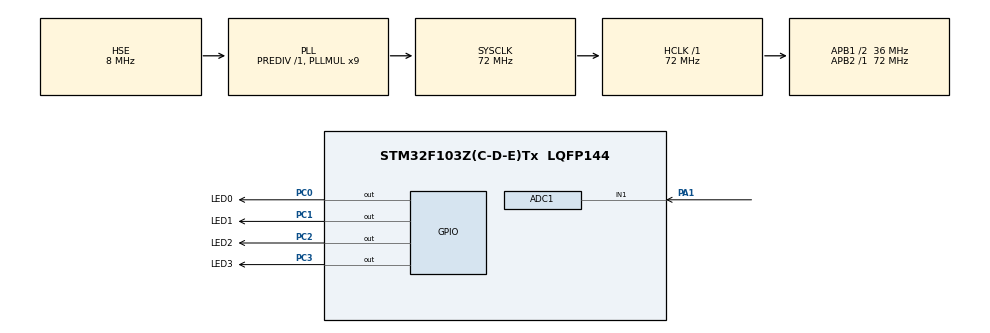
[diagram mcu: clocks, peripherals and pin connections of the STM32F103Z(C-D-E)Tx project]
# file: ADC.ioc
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ADC1.Channel-4\#ChannelRegularConversion=ADC_CHANNEL_1
ADC1.NbrOfConversionFlag=1
ADC1.Rank-4\#ChannelRegularConversion=1
ADC1.SamplingTime-4\#ChannelRegularConversion=ADC_SAMPLETIME_1CYCLE_5
ADC1.master=1
Mcu.Family=STM32F1
Mcu.Name=STM32F103Z(C-D-E)Tx
Mcu.Package=LQFP144
NVIC.ADC1_2_IRQn=true\:0\:0\:false\:false\:true\:true\:true
NVIC.PriorityGroup=NVIC_PRIORITYGROUP_4
OSC_IN.Mode=HSE-External-Oscillator
OSC_IN.Signal=RCC_OSC_IN
OSC_OUT.Mode=HSE-External-Oscillator
OSC_OUT.Signal=RCC_OSC_OUT
PA1.Signal=ADCx_IN1
PA13.Mode=Serial_Wire
PA13.Signal=SYS_JTMS-SWDIO
PA14.Mode=Serial_Wire
PA14.Signal=SYS_JTCK-SWCLK
PC0.GPIO_Label=LED0
PC0.GPIO_ModeDefaultOutputPP=GPIO_MODE_OUTPUT_PP
PC0.GPIO_PuPd=GPIO_NOPULL
PC0.GPIO_Speed=GPIO_SPEED_FREQ_LOW
PC0.PinState=GPIO_PIN_SET
PC0.Signal=GPIO_Output
PC1.GPIO_Label=LED1
PC1.GPIO_ModeDefaultOutputPP=GPIO_MODE_OUTPUT_PP
PC1.GPIO_PuPd=GPIO_NOPULL
PC1.GPIO_Speed=GPIO_SPEED_FREQ_LOW
PC1.PinState=GPIO_PIN_SET
PC1.Signal=GPIO_Output
PC2.GPIO_Label=LED2
PC2.GPIO_ModeDefaultOutputPP=GPIO_MODE_OUTPUT_PP
PC2.GPIO_PuPd=GPIO_NOPULL
PC2.GPIO_Speed=GPIO_SPEED_FREQ_LOW
PC2.PinState=GPIO_PIN_SET
PC2.Signal=GPIO_Output
PC3.GPIO_Label=LED3
PC3.GPIO_ModeDefaultOutputPP=GPIO_MODE_OUTPUT_PP
PC3.GPIO_PuPd=GPIO_NOPULL
PC3.GPIO_Speed=GPIO_SPEED_FREQ_LOW
PC3.PinState=GPIO_PIN_SET
PC3.Signal=GPIO_Output
ProjectManager.HeapSize=0x200
ProjectManager.StackSize=0x400
ProjectManager.TargetToolchain=MDK-ARM V5.27
RCC.ADCPresc=RCC_ADCPCLK2_DIV6
RCC.AHBFreq_Value=72000000
RCC.APB1CLKDivider=RCC_HCLK_DIV2
RCC.APB1Freq_Value=36000000
RCC.APB1TimFreq_Value=72000000
RCC.APB2Freq_Value=72000000
RCC.APB2TimFreq_Value=72000000
RCC.HCLKFreq_Value=72000000
RCC.PLLMUL=RCC_PLL_MUL9
RCC.PLLSourceVirtual=RCC_PLLSOURCE_HSE
RCC.SYSCLKFreq_VALUE=72000000
RCC.SYSCLKSource=RCC_SYSCLKSOURCE_PLLCLK
RCC.USBFreq_Value=48000000
RCC.USBPrescaler=RCC_USBCLKSOURCE_PLL_DIV1_5
SH.ADCx_IN1.0=ADC1_IN1,IN1
board=custom

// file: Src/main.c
/* USER CODE BEGIN Header */
/**
  ******************************************************************************
  * @file           : main.c
  * @brief          : Main program body
  ******************************************************************************
  * @attention
  *
  * <h2><center>&copy; Copyright (c) 2020 STMicroelectronics.
  * All rights reserved.</center></h2>
  *
  * This software component is licensed by ST under BSD 3-Clause license,
  * the "License"; You may not use this file except in compliance with the
  * License. You may obtain a copy of the License at:
  *                        opensource.org/licenses/BSD-3-Clause
  *
  ******************************************************************************
  */
/* USER CODE END Header */

#include "main.h"
#include "adc.h"
#include "gpio.h"

/* USER CODE BEGIN Includes */
#include <stdio.h>
/* USER CODE END Includes */

void SystemClock_Config(void);

/* USER CODE BEGIN 0 */
int fputc(int ch, FILE *f)
{
	return ITM_SendChar(ch);
}
/* USER CODE END 0 */

int main(void)
{

  /* MCU Configuration--------------------------------------------------------*/

  /* Reset of all peripherals, Initializes the Flash interface and the Systick. */
  HAL_Init();

  /* Configure the system clock */
  SystemClock_Config();

  /* Initialize all configured peripherals */
  MX_GPIO_Init();
  MX_ADC1_Init();

  /* Infinite loop */
  while (1)
  {

    /* USER CODE BEGIN 3 */
		HAL_ADC_Start(&hadc1);
		HAL_ADC_PollForConversion(&hadc1, 10);
		uint32_t value = 0;
		printf("\n\rvalue:%.2fV", (value = HAL_ADC_GetValue(&hadc1))/4096.0*3.3);//ֱ�Ӳɼ��޴��������ܲ�׼ȷ
		HAL_GPIO_WritePin(GPIOC, 0x0f, GPIO_PIN_SET);
		HAL_GPIO_WritePin(GPIOC,value/4096.0*16, GPIO_PIN_RESET);

  }
  /* USER CODE END 3 */
}

void SystemClock_Config(void)
{
  RCC_OscInitTypeDef RCC_OscInitStruct = {0};
  RCC_ClkInitTypeDef RCC_ClkInitStruct = {0};
  RCC_PeriphCLKInitTypeDef PeriphClkInit = {0};

  /** Initializes the CPU, AHB and APB busses clocks
  */
  RCC_OscInitStruct.OscillatorType = RCC_OSCILLATORTYPE_HSE;
  RCC_OscInitStruct.HSEState = RCC_HSE_ON;
  RCC_OscInitStruct.HSEPredivValue = RCC_HSE_PREDIV_DIV1;
  RCC_OscInitStruct.HSIState = RCC_HSI_ON;
  RCC_OscInitStruct.PLL.PLLState = RCC_PLL_ON;
  RCC_OscInitStruct.PLL.PLLSource = RCC_PLLSOURCE_HSE;
  RCC_OscInitStruct.PLL.PLLMUL = RCC_PLL_MUL9;
  if (HAL_RCC_OscConfig(&RCC_OscInitStruct) != HAL_OK)
  {
    Error_Handler();
  }
  /** Initializes the CPU, AHB and APB busses clocks
  */
  RCC_ClkInitStruct.ClockType = RCC_CLOCKTYPE_HCLK|RCC_CLOCKTYPE_SYSCLK
                              |RCC_CLOCKTYPE_PCLK1|RCC_CLOCKTYPE_PCLK2;
  RCC_ClkInitStruct.SYSCLKSource = RCC_SYSCLKSOURCE_PLLCLK;
  RCC_ClkInitStruct.AHBCLKDivider = RCC_SYSCLK_DIV1;
  RCC_ClkInitStruct.APB1CLKDivider = RCC_HCLK_DIV2;
  RCC_ClkInitStruct.APB2CLKDivider = RCC_HCLK_DIV1;

  if (HAL_RCC_ClockConfig(&RCC_ClkInitStruct, FLASH_LATENCY_2) != HAL_OK)
  {
    Error_Handler();
  }
  PeriphClkInit.PeriphClockSelection = RCC_PERIPHCLK_ADC;
  PeriphClkInit.AdcClockSelection = RCC_ADCPCLK2_DIV6;
  if (HAL_RCCEx_PeriphCLKConfig(&PeriphClkInit) != HAL_OK)
  {
    Error_Handler();
  }
}

void Error_Handler(void)
{
}

/************************ (C) COPYRIGHT STMicroelectronics *****END OF FILE****/
